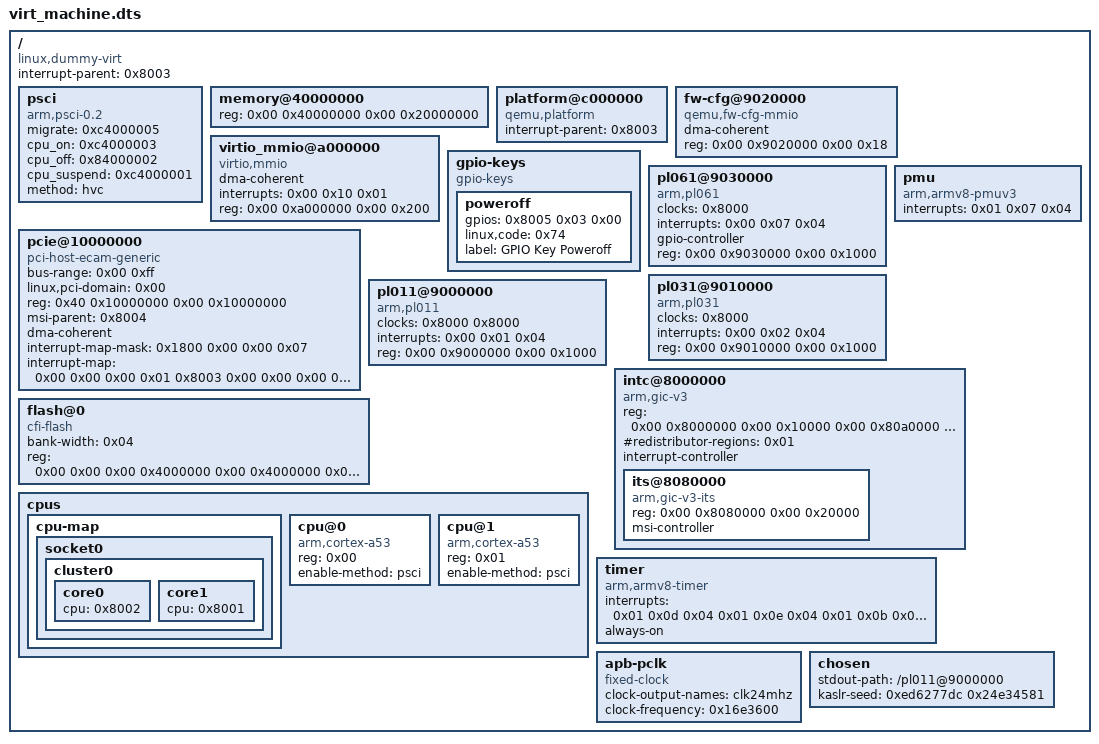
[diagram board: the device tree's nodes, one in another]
// ============================================================
// virt_machine.dts — QEMU virt 机器的设备树（注释学习版）
// ============================================================
// 这个文件不是手写的：它是 QEMU 每次启动时【现场生成】、按 ARM64
// 启动协议放进 x0 寄存器传给内核的那张设备树。本文件是导出后加了
// 中文注释的学习副本。
//
// 如何重新导出（QEMU 版本需支持 -machine dumpdtb）：
//   qemu-system-aarch64 -M virt,gic-version=3 -cpu cortex-a53 \
//       -m 512M -smp 2 -machine dumpdtb=virt.dtb
//   dtc -I dtb -O dts virt.dtb > virt_machine.dts   # 反编译
//
// 三个关键认知（面试考点）：
// 1. 真实板子的 DT 是 .dtb 文件存 SD/eMMC 里由 U-Boot 加载；
//    本项目没有 U-Boot，DT 由 QEMU 动态生成。
// 2. 这张图里【没有 nvme 节点】——PCIe 设备是可自描述的（配置空间
//    里有 vendor/device ID），内核靠扫描 PCI 配置空间枚举，不靠 DT。
//    DT 只描述不可枚举的平台设备（UART/GPIO/中断控制器/时钟）。
// 3. 真机调 NVMe 时 DT 要写的是【PCIe 主机桥】节点（clocks/resets/
//    vcc3v3-supply/reset-gpios 给 SSD 供电复位），本项目 QEMU 替你把
//    板级做完了。
// ============================================================

/dts-v1/;

/ {
	// 根节点属性：中断默认父节点 = phandle 0x8003（GICv3）
	// #address-cells=2 / #size-cells=2：reg 里地址和长度都是 2 个 u32（64 位平台）
	interrupt-parent = <0x8003>;
	#size-cells = <0x02>;
	#address-cells = <0x02>;
	compatible = "linux,dummy-virt";

	// ---- PSCI：电源管理接口，QEMU 的"固件"提供 ----
	// 内核通过 hvc 指令呼叫 QEMU 完成开关核等操作。
	// 下面 cpus 节点里 cpu@0/1 的 enable-method = "psci" 就是用它启动副核
	psci {
		migrate = <0xc4000005>;
		cpu_on = <0xc4000003>;
		cpu_off = <0x84000002>;
		cpu_suspend = <0xc4000001>;
		method = "hvc";
		compatible = "arm,psci-0.2\0arm,psci";
	};

	// ---- 内存：512M，物理地址从 0x40000000 开始 ----
	// 对应脚本 -m 512M。改 -m 1G 这里会变成 0x40000000
	memory@40000000 {
		reg = <0x00 0x40000000 0x00 0x20000000>;
		device_type = "memory";
	};

	// ---- 平台总线（simple-bus）：QEMU 的老式 MMIO 设备挂这里 ----
	platform@c000000 {
		interrupt-parent = <0x8003>;
		ranges = <0x00 0x00 0xc000000 0x2000000>;
		#address-cells = <0x01>;
		#size-cells = <0x01>;
		compatible = "qemu,platform\0simple-bus";
	};

	// ---- fw-cfg：QEMU 向 guest 传配置信息的通道 ----
	fw-cfg@9020000 {
		dma-coherent;
		reg = <0x00 0x9020000 0x00 0x18>;
		compatible = "qemu,fw-cfg-mmio";
	};

	// ---- virtio_mmio：32 个 virtio 设备槽位（本项目没用，注释掉 31 个重复的）----
	// 每个槽位 0x200 字节，从 0xa000000 到 0xa003e00，中断号递增（SPI 16~47）。
	// 脚本里没用 -device virtio-blk，所以这些槽位都空着。
	// 示例（第一个槽位）：
	virtio_mmio@a000000 {
		dma-coherent;                          // 见下面 pcie 节点同款注释
		interrupts = <0x00 0x10 0x01>;         // GIC SPI 16，边沿触发
		reg = <0x00 0xa000000 0x00 0x200>;
		compatible = "virtio,mmio";
	};
	// ...（a000200 ~ a003e00 共 31 个同结构节点，此处省略）...

	// ---- GPIO 按键：关机键（Ctrl+a x 之外的另一种关机方式）----
	gpio-keys {
		#address-cells = <0x01>;
		#size-cells = <0x00>;
		compatible = "gpio-keys";

		poweroff {
			gpios = <0x8005 0x03 0x00>;    // phandle 0x8005 = 下面的 pl061 GPIO 控制器
			linux,code = <0x74>;
			label = "GPIO Key Poweroff";
		};
	};

	// ---- pl061 GPIO 控制器 ----
	pl061@9030000 {
		phandle = <0x8005>;
		clock-names = "apb_pclk";
		clocks = <0x8000>;                  // 时钟 = 下面的 apb-pclk（24MHz）
		interrupts = <0x00 0x07 0x04>;      // GIC SPI 7，高电平触发
		gpio-controller;
		#gpio-cells = <0x02>;
		compatible = "arm,pl061\0arm,primecell";
		reg = <0x00 0x9030000 0x00 0x1000>;
	};

	// ════════════════════════════════════════════════════════
	// PCIe 主机桥（gpex）—— 本项目的核心节点，逐字段精读
	// ════════════════════════════════════════════════════════
	pcie@10000000 {
		// compatible = "pci-host-ecam-generic"：由内核通用 ECAM 驱动
		// （drivers/pci/controller/pci-host-generic.c）接管，不需要芯片厂商
		// 专属驱动。真机（i.MX8/RK3588）这里是 "rockchip,rk3588-pcie3" 之类。
		compatible = "pci-host-ecam-generic";
		device_type = "pci";
		// PCI 地址三元组 (bus#, dev#, func#)：bus 8 位，dev 5 位，func 3 位
		#address-cells = <0x03>;
		#size-cells = <0x02>;
		bus-range = <0x00 0xff>;            // 可枚举的总线号 0~255
		linux,pci-domain = <0x00>;

		// reg：ECAM 配置空间窗口，基址 0x40_1000_0000，大小 0x10000000（256MB）。
		// ECAM 规则：每个总线号固定 1MB 配置空间，256 个总线正好 256MB。
		// 内核枚举时访问总线 n 设备 m 的配置空间，就是访问
		// 0x40_1000_0000 + n*1MB + m*8KB + 偏移。
		reg = <0x40 0x10000000 0x00 0x10000000>;

		// ranges：把 PCI 侧地址翻译成 CPU 侧（父总线）地址，三段式：
		//   <0x1000000 0x0       0x0         0x0 0x3eff0000  0x0  0x10000>    IO 空间
		//   <0x2000000 0x0 0x10000000         0x0 0x10000000  0x0 0x2eff0000> MEM32 空间
		//   <0x3000000 0x80 0x0               0x80 0x0         0x80 0x0>       MEM64 空间
		// 解码规则（MEM32 为例）：PCI 地址 0x10000000 起、长 0x2eff0000（约 751MB）
		// 的区域，映射到 CPU 地址 0x10000000。所以 NVMe 的 BAR0 MMIO 寄存器
		// 就落在这个窗口里（guest 里看 BAR0 约 0x10000000）。
		// 0x1000000=IO、0x2000000=MEM32、0x3000000=MEM64 是 DT 规范写死的类型码。
		ranges = <0x1000000 0x00 0x00 0x00 0x3eff0000 0x00 0x10000 0x2000000 0x00 0x10000000 0x00 0x10000000 0x00 0x2eff0000 0x3000000 0x80 0x00 0x80 0x00 0x80 0x00>;

		// msi-parent = phandle 0x8004 = GIC 里的 its@8080000 节点。
		// MSI/MSI-X 中断的本质是"设备向一段特殊内存地址写数据"，
		// 这段地址就是 ITS 的 MSI 地址窗口（GICv3 + ITS 才有，串起项目坑 8：
		// 为什么脚本必须 gic-version=3）。
		msi-parent = <0x8004>;

		// dma-coherent：guest 里所有设备与 CPU 是缓存一致的，
		// 驱动不需要显式 cache flush。这是 QEMU 与多数真实 ARM 板
		// 的差异点之一（真机上很多平台必须维护缓存一致性）。
		dma-coherent;

		// interrupt-map：传统 INTx 引脚中断的路由表。
		// 格式：<子地址 中断引脚 父控制器 父中断 触发方式>
		// 本例把 slot 0~31 的 INTA/B/C/D 全映射到 GIC SPI 3~6。
		// NVMe 用 MSI-X 不走这条表，但内核枚举初期（配置空间访问前）
		// 可能先用 INTx。
		interrupt-map-mask = <0x1800 0x00 0x00 0x07>;
		interrupt-map = <0x00 0x00 0x00 0x01 0x8003 0x00 0x00 0x00 0x03 0x04 0x00 0x00 0x00 0x02 0x8003 0x00 0x00 0x00 0x04 0x04 0x00 0x00 0x00 0x03 0x8003 0x00 0x00 0x00 0x05 0x04 0x00 0x00 0x00 0x04 0x8003 0x00 0x00 0x00 0x06 0x04 0x800 0x00 0x00 0x01 0x8003 0x00 0x00 0x00 0x04 0x04 0x800 0x00 0x00 0x02 0x8003 0x00 0x00 0x00 0x05 0x04 0x800 0x00 0x00 0x03 0x8003 0x00 0x00 0x00 0x06 0x04 0x800 0x00 0x00 0x04 0x8003 0x00 0x00 0x00 0x03 0x04 0x1000 0x00 0x00 0x01 0x8003 0x00 0x00 0x00 0x05 0x04 0x1000 0x00 0x00 0x02 0x8003 0x00 0x00 0x00 0x06 0x04 0x1000 0x00 0x00 0x03 0x8003 0x00 0x00 0x00 0x03 0x04 0x1000 0x00 0x00 0x04 0x8003 0x00 0x00 0x00 0x04 0x04 0x1800 0x00 0x00 0x01 0x8003 0x00 0x00 0x00 0x06 0x04 0x1800 0x00 0x00 0x02 0x8003 0x00 0x00 0x00 0x03 0x04 0x1800 0x00 0x00 0x03 0x8003 0x00 0x00 0x00 0x04 0x04 0x1800 0x00 0x00 0x04 0x8003 0x00 0x00 0x00 0x05 0x04>;
		#interrupt-cells = <0x01>;
	};

	// ---- PL031 RTC（实时时钟）----
	pl031@9010000 {
		clock-names = "apb_pclk";
		clocks = <0x8000>;
		interrupts = <0x00 0x02 0x04>;
		reg = <0x00 0x9010000 0x00 0x1000>;
		compatible = "arm,pl031\0arm,primecell";
	};

	// ---- PL011 串口（就是 ttyAMA0，脚本 console=ttyAMA0 的由来）----
	pl011@9000000 {
		clock-names = "uartclk\0apb_pclk";
		clocks = <0x8000 0x8000>;
		interrupts = <0x00 0x01 0x04>;      // GIC SPI 1
		reg = <0x00 0x9000000 0x00 0x1000>;
		compatible = "arm,pl011\0arm,primecell";
	};

	// ---- PMU 性能计数器 ----
	pmu {
		interrupts = <0x01 0x07 0x04>;      // PPI 7
		compatible = "arm,armv8-pmuv3";
	};

	// ════════════════════════════════════════════════════════
	// GICv3 中断控制器 + ITS —— MSI-X 能工作的根基
	// ════════════════════════════════════════════════════════
	intc@8000000 {
		phandle = <0x8003>;                 // 全图 0x8003 都指向这里
		// distributor 0x8000000 + redistributor 0x80a0000
		reg = <0x00 0x8000000 0x00 0x10000 0x00 0x80a0000 0x00 0xf60000>;
		#redistributor-regions = <0x01>;
		compatible = "arm,gic-v3";
		ranges;
		#size-cells = <0x02>;
		#address-cells = <0x02>;
		interrupt-controller;
		#interrupt-cells = <0x03>;          // <类型 SPI=0/PPI=1 中断号 触发方式>

		its@8080000 {
			phandle = <0x8004>;             // pcie 节点的 msi-parent 指向这里
			reg = <0x00 0x8080000 0x00 0x20000>;
			msi-controller;                 // 声明"我是 MSI 控制器"
			compatible = "arm,gic-v3-its";
		};
	};

	// ---- pflash：两块 64MB CFI Flash（存固件/bootloader 用，本项目未用）----
	flash@0 {
		bank-width = <0x04>;
		reg = <0x00 0x00 0x00 0x4000000 0x00 0x4000000 0x00 0x4000000>;
		compatible = "cfi-flash";
	};

	// ---- CPU：2 个 Cortex-A53（对应 -smp 2）----
	cpus {
		#size-cells = <0x00>;
		#address-cells = <0x01>;

		// cpu-map 描述拓扑：单 socket / 单 cluster / 双核
		cpu-map {
			socket0 {
				cluster0 {
					core0 { cpu = <0x8002>; };
					core1 { cpu = <0x8001>; };
				};
			};
		};

		cpu@0 {
			phandle = <0x8002>;
			reg = <0x00>;
			enable-method = "psci";         // 内核用 PSCI 开机/唤醒这个核
			compatible = "arm,cortex-a53";
			device_type = "cpu";
		};

		cpu@1 {
			phandle = <0x8001>;
			reg = <0x01>;
			enable-method = "psci";
			compatible = "arm,cortex-a53";
			device_type = "cpu";
		};
	};

	// ---- ARMv8 架构定时器 ----
	timer {
		interrupts = <0x01 0x0d 0x04 0x01 0x0e 0x04 0x01 0x0b 0x04 0x01 0x0a 0x04>;
		always-on;
		compatible = "arm,armv8-timer\0arm,armv7-timer";
	};

	// ---- 固定 24MHz 时钟（0x16e3600 = 24000000）----
	// 全图 clocks = <0x8000> 都指向它——QEMU 里没有真实时钟树，
	// 统一给一个固定频率时钟。
	apb-pclk {
		phandle = <0x8000>;
		clock-output-names = "clk24mhz";
		clock-frequency = <0x16e3600>;
		#clock-cells = <0x00>;
		compatible = "fixed-clock";
	};

	// ---- chosen：内核启动参数通道 ----
	// stdout-path 指定串口控制台 → 内核早期打印走 pl011@9000000，
	// 这就是脚本里 console=ttyAMA0 与它呼应的原因。
	// kaslr-seed：KASLR 随机化种子，QEMU 每次启动随机生成——
	// 所以每次 dump 出来这个值都不一样。
	chosen {
		stdout-path = "/pl011@9000000";
		kaslr-seed = <0xed6277dc 0x24e34581>;
	};
};

// ════════════════════════════════════════════════════════════
// 学习路线建议（配合 LEARN.md 阶段 0）
// ════════════════════════════════════════════════════════════
// 1. 精读 pcie@10000000 节点：ranges 三段解码、ECAM 窗口、
//    msi-parent→ITS 链路（串起坑 8）、dma-coherent、interrupt-map。
// 2. 改着玩验证：
//      a. 改 stdout-path 或注释掉 kaslr-seed → dtc -I dts -O dtb 编回
//      b. 启动脚本加 -dtb 参数启动 → 观察行为变化（如串口不输出）
//      证明你掌握"改 dts → 编 dtb → 加载"完整闭环（真机同一套流程）。
// 3. 面试必答：
//      Q: 你的 NVMe 驱动靠设备树匹配吗？
//      A: 不靠。PCIe 设备靠配置空间 vendor/device ID 枚举（自描述），
//         DT 只描述不可枚举的平台设备；真机 BSP 的 DT 工作是为
//         PCIe 主机桥配 clocks/resets/供电复位，QEMU 替我省掉了板级部分。
